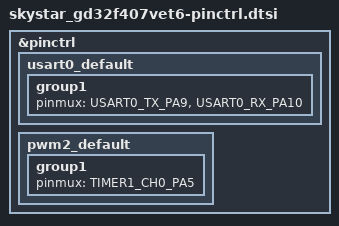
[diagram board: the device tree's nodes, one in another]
/*
 * Copyright (c) 2025, Liu Changjie <liucj1228@outlook.com>
 * SPDX-License-Identifier: Apache-2.0
 */

#include <dt-bindings/pinctrl/gd32f405z(e-g-k)xx-pinctrl.h>

&pinctrl {
	usart0_default: usart0_default {
		group1 {
			pinmux = <USART0_TX_PA9>, <USART0_RX_PA10>;
		};
	};

	pwm2_default: pwm2_default {
		group1 {
			pinmux = <TIMER1_CH0_PA5>;
		};
	};
};
